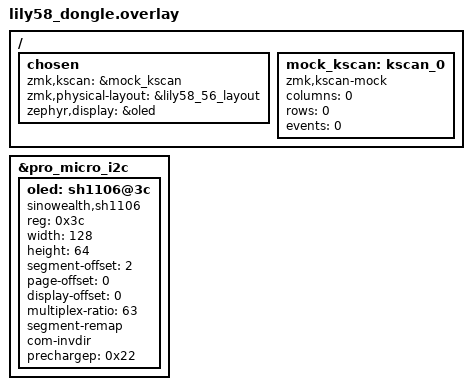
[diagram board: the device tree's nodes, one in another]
/* Shared 56-key Lily58 layout (same file the halves use) */
#include "../../../config/lily58_56.dtsi"

/ {
    chosen {
        zmk,kscan = &mock_kscan;
        zmk,physical-layout = &lily58_56_layout;
        zephyr,display = &oled;
    };

    /* The dongle has no keys */
    mock_kscan: kscan_0 {
        compatible = "zmk,kscan-mock";
        columns = <0>;
        rows = <0>;
        events = <0>;
    };
};

/*
 * 1.3" 128x64 OLED = SH1106 controller (I2C)
 * Wiring on the dongle nice!nano:
 *   GND -> GND
 *   VCC -> VCC (3.3V)
 *   SDA -> D2  (P0.17)
 *   SCL -> D3  (P0.20)
 */
&pro_micro_i2c {
    status = "okay";

    oled: sh1106@3c {
        compatible = "sinowealth,sh1106";
        reg = <0x3c>;
        width = <128>;
        height = <64>;
        segment-offset = <2>;
        page-offset = <0>;
        display-offset = <0>;
        multiplex-ratio = <63>;
        segment-remap;
        com-invdir;
        prechargep = <0x22>;
    };
};
